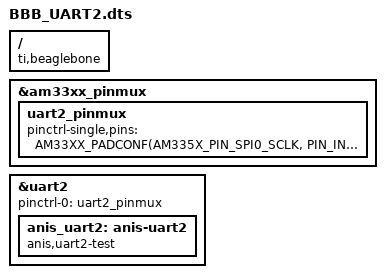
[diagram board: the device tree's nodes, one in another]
/dts-v1/;
/plugin/;

#include <dt-bindings/pinctrl/am33xx.h>

/ {
    compatible = "ti,beaglebone", "ti,beaglebone-black";

    fragment@0 {
        target = <&am33xx_pinmux>;
        __overlay__ {
            uart2_pinmux: uart2_pinmux {
                pinctrl-single,pins = <
                    AM33XX_PADCONF(AM335X_PIN_SPI0_SCLK, PIN_INPUT_PULLUP,  MUX_MODE1)
                    AM33XX_PADCONF(AM335X_PIN_SPI0_D0,   PIN_OUTPUT_PULLUP, MUX_MODE1)
                >;
            };
        };
    };

    fragment@1 {
        target = <&uart2>;
        __overlay__ {
            pinctrl-names = "default";
            pinctrl-0 = <&uart2_pinmux>;
            status = "okay";

            anis_uart2: anis-uart2 {
                compatible = "anis,uart2-test";
                status = "okay";
            };
        };
    };
};
